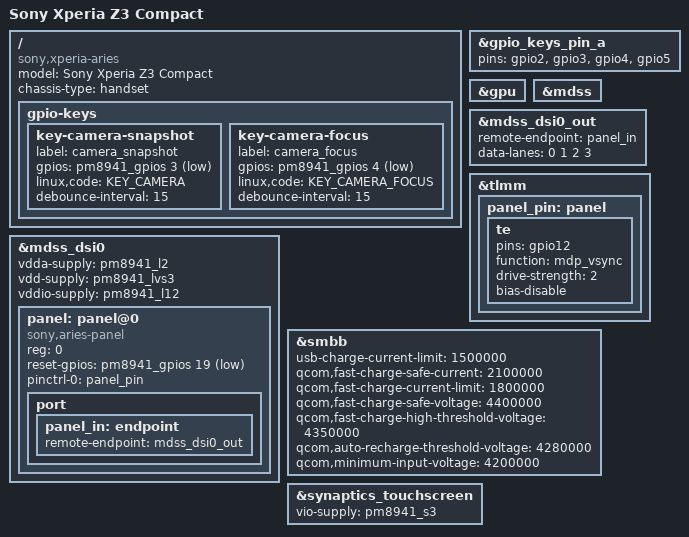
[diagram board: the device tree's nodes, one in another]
// SPDX-License-Identifier: GPL-2.0
#include "qcom-msm8974pro-sony-xperia-shinano-common.dtsi"

/ {
	model = "Sony Xperia Z3 Compact";
	compatible = "sony,xperia-aries", "qcom,msm8974pro", "qcom,msm8974";
	chassis-type = "handset";

	gpio-keys {
		key-camera-snapshot {
			label = "camera_snapshot";
			gpios = <&pm8941_gpios 3 GPIO_ACTIVE_LOW>;
			linux,code = <KEY_CAMERA>;
			debounce-interval = <15>;
		};

		key-camera-focus {
			label = "camera_focus";
			gpios = <&pm8941_gpios 4 GPIO_ACTIVE_LOW>;
			linux,code = <KEY_CAMERA_FOCUS>;
			debounce-interval = <15>;
		};
	};
};

&gpio_keys_pin_a {
	pins = "gpio2", "gpio3", "gpio4", "gpio5";
};

&gpu {
	status = "okay";
};

&mdss {
	status = "okay";
};

&mdss_dsi0 {
	status = "okay";

	vdda-supply = <&pm8941_l2>;
	vdd-supply = <&pm8941_lvs3>;
	vddio-supply = <&pm8941_l12>;

	panel: panel@0 {
		reg = <0>;
		compatible = "sony,aries-panel";

		reset-gpios = <&pm8941_gpios 19 GPIO_ACTIVE_LOW>;

		pinctrl-names = "default";
		pinctrl-0 = <&panel_pin>;

		port {
			panel_in: endpoint {
				remote-endpoint = <&mdss_dsi0_out>;
			};
		};
	};
};

&mdss_dsi0_out {
	remote-endpoint = <&panel_in>;
	data-lanes = <0 1 2 3>;
};

&tlmm {
	panel_pin: panel {
		te {
			pins = "gpio12";
			function = "mdp_vsync";

			drive-strength = <2>;
			bias-disable;
		};
	};
};

&smbb {
	usb-charge-current-limit = <1500000>;
	qcom,fast-charge-safe-current = <2100000>;
	qcom,fast-charge-current-limit = <1800000>;
	qcom,fast-charge-safe-voltage = <4400000>;
	qcom,fast-charge-high-threshold-voltage = <4350000>;
	qcom,auto-recharge-threshold-voltage = <4280000>;
	qcom,minimum-input-voltage = <4200000>;

	status = "okay";
};

&synaptics_touchscreen {
	vio-supply = <&pm8941_s3>;
};
